# max32572 register map
Vendor: Maxim-Integrated; Series: ARMCM4; File version: 1.0
CPU: CM4 r2p1, little endian, MPU, FPU, 3 interrupt priority bits
Registers are 32-bit, read-write, reset 0x0 unless marked. A register's access mark holds for its fields unless they carry their own. Offsets are from the block's base; [hi:lo] are bit positions; {n}, {i} and the like mark numbered series.

## ADC — 10-bit Analog to Digital Converter
Base 0x40034000
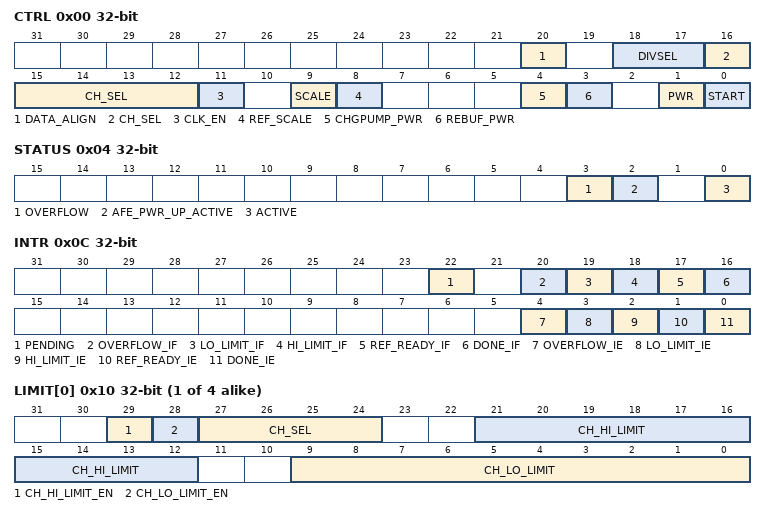
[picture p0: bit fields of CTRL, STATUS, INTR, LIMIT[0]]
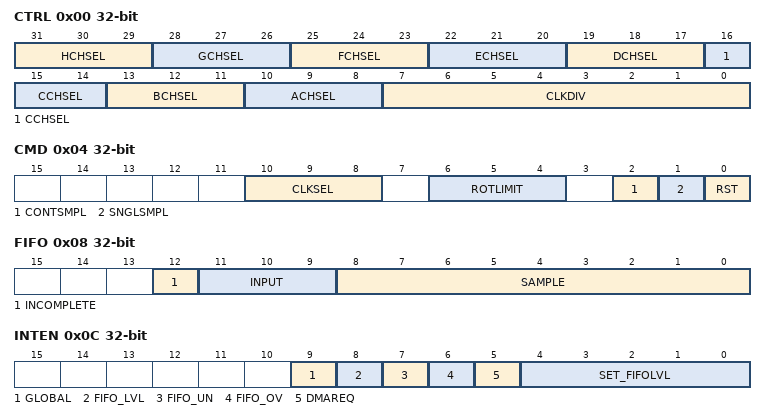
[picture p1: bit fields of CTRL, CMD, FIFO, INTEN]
0x00 CTRL — ADC Control
  [20] DATA_ALIGN — ADC Data Alignment Select
  [18:17] DIVSEL — Scales the external inputs, all inputs are scaled the same
    {v}=DIV{v+1} (v=0..3)
  [16:12] CH_SEL — ADC Channel Select
    {v}=AIN{v} (v=0..7); 8=VcoreA; 9=VcoreB; 10=Vrxout; 11=Vtxout; 12=VddA; 13=VddB/4; 14=Vddio/4; 15=Vddioh/4; 16=VregI/4
  [11] CLK_EN — ADC Clock Enable
  [9] SCALE — ADC Scale
  [8] REF_SCALE — ADC Reference Scale
  [4] CHGPUMP_PWR — ADC Charge Pump Power Up
  [3] REBUF_PWR — ADC Reference Buffer Power Up
  [1] PWR — ADC Power Up
  [0] START — Start ADC Conversion
0x04 STATUS — ADC Status
  [3] OVERFLOW ro — ADC Overflow
  [2] AFE_PWR_UP_ACTIVE ro — AFE Power Up Delay Active
  [0] ACTIVE ro — ADC Conversion In Progress
0x08 DATA — ADC Output Data
  [15:0] DATA ro — ADC Converted Sample Data Output
0x0C INTR — ADC Interrupt Control Register
  [22] PENDING ro — ADC Interrupt Pending Status
  [20] OVERFLOW_IF write-1-clears — ADC Overflow Interrupt Flag
  [19] LO_LIMIT_IF write-1-clears — ADC Lo Limit Monitor Interrupt Flag
  [18] HI_LIMIT_IF write-1-clears — ADC Hi Limit Monitor Interrupt Flag
  [17] REF_READY_IF write-1-clears — ADC Reference Ready Interrupt Flag
  [16] DONE_IF write-1-clears — ADC Done Interrupt Flag
  [4] OVERFLOW_IE — ADC Overflow Interrupt Enable
  [3] LO_LIMIT_IE — ADC Lo Limit Monitor Interrupt Enable
  [2] HI_LIMIT_IE — ADC Hi Limit Monitor Interrupt Enable
  [1] REF_READY_IE — ADC Reference Ready Interrupt Enable
  [0] DONE_IE — ADC Done Interrupt Enable
{0x10+4i} LIMIT[{i}] (i=0..3) — ADC Limit
  [29] CH_HI_LIMIT_EN — High Limit Monitoring Enable
  [28] CH_LO_LIMIT_EN — Low Limit Monitoring Enable
  [27:24] CH_SEL — ADC Channel Select
  [21:12] CH_HI_LIMIT — High Limit Threshold
  [9:0] CH_LO_LIMIT — Low Limit Threshold
0x20 DECCNT — ADC Decimation Count.
  [31:0] DELAY

## AESKEYS — AES Key Registers.
Base 0x40005000
{0x0+4i} MEU[{i}] (i=0..7) — AES-256 SRAM Encryption Key (MEU).
{0x20+4i} XIP[{i}] (i=0..3) — AES-128 QSPI Code Key (MEMPROT XIP).

## MSRADC — Magnetic Strip Reader - 9 bit ADC
Base 0x4002B000
0x00 CTRL — ADC Control
  [31:29] HCHSEL — H Channel ADC Input Pin Selection.
    0=invalid; 1=CH1_IN; 2=CH2_IN; 3=CH3_IN
  [28:26] GCHSEL — G Channel ADC Input Pin Selection.
    0=invalid; 1=CH1_IN; 2=CH2_IN; 3=CH3_IN
  [25:23] FCHSEL — F Channel ADC Input Pin Selection.
    0=invalid; 1=CH1_IN; 2=CH2_IN; 3=CH3_IN
  [22:20] ECHSEL — E Channel ADC Input Pin Selection.
    0=invalid; 1=CH1_IN; 2=CH2_IN; 3=CH3_IN
  [19:17] DCHSEL — D Channel ADC Input Pin Selection.
    0=invalid; 1=CH1_IN; 2=CH2_IN; 3=CH3_IN
  [16:14] CCHSEL — C Channel ADC Input Pin Selection.
    0=invalid; 1=CH1_IN; 2=CH2_IN; 3=CH3_IN
  [13:11] BCHSEL — B Channel ADC Input Pin Selection.
    0=invalid; 1=CH1_IN; 2=CH2_IN; 3=CH3_IN
  [10:8] ACHSEL — A Channel ADC Input Pin Selection.
    0=invalid; 1=CH1_IN; 2=CH2_IN; 3=CH3_IN
  [7:0] CLKDIV — ADC Clock Divider.
0x04 CMD — MSRADC Command
  [10:8] CLKSEL — Clock Select.
    0=3_samples; 1=5_samples; 2=4_samples; 3=8_samples; 4=16_samples; 5=32_samples; 6=64_samples; 7=128_samples
  [6:4] ROTLIMIT — Rotation Limit.
    0=1_channel; {v}={v+1}_channels (v=1..7)
  [2] CONTSMPL — Continuous Sample Mode Enable.
  [1] SNGLSMPL — Single Sample Mode.
  [0] RST — ADC Reset.
0x08 FIFO — ADC FIFO
  [12] INCOMPLETE ro — ADC Incomplete.
  [11:9] INPUT ro — ADC Sample Pin
    0=invalid; {v}=CH{v}_IN (v=1..7)
  [8:0] SAMPLE ro — ADC Converted Sample Data Output
0x0C INTEN — ADC Interrupt Enable Register
  [9] GLOBAL — ADC Global Interrupt Enable.
  [8] FIFO_LVL — FIFO Level Interrupt Enable.
  [7] FIFO_UN — FIFO Underflow Interrupt Enable.
  [6] FIFO_OV — FIFO Overflow Interrupt Enable.
  [5] DMAREQ — DMA Request Enable.
  [4:0] SET_FIFOLVL — Set FIFO Interrupt Level.
    {v}=at_least_{v+1} (v=0..15)
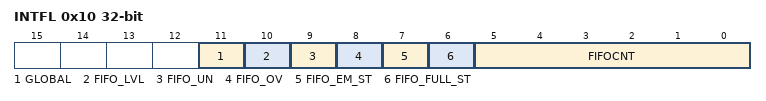
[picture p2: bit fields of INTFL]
0x10 INTFL — ADC Interrupt Flag Register.
  [11] GLOBAL ro — ADC Global Interrupt Flag.
  [10] FIFO_LVL ro — FIFO Level Status.
  [9] FIFO_UN ro — FIFO Underflow Status.
  [8] FIFO_OV ro — FIFO Overflow Status.
  [7] FIFO_EM_ST ro — FIFO Empty Status.
  [6] FIFO_FULL_ST ro — FIFO Full Status.
  [5:0] FIFOCNT ro — FIFO Count.
